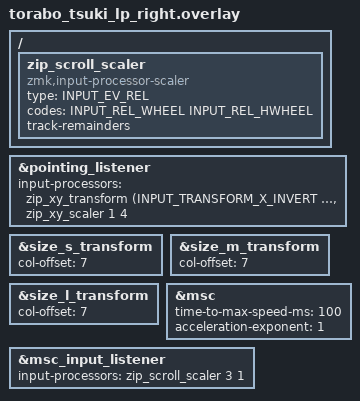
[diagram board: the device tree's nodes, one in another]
#include "torabo_tsuki_lp.dtsi"
#include <input/processors.dtsi>
#include <dt-bindings/zmk/input_transform.h>

&pointing_listener {
    input-processors = <
      &zip_xy_transform (INPUT_TRANSFORM_X_INVERT | INPUT_TRANSFORM_Y_INVERT)
      &zip_xy_scaler 1 4
    >;
};

&size_s_transform {
    col-offset = <7>;
};

&size_m_transform {
    col-offset = <7>;
};

&size_l_transform {
    col-offset = <7>;
};

#include <zephyr/dt-bindings/input/input-event-codes.h>

/ {
    zip_scroll_scaler: zip_scroll_scaler {
        compatible = "zmk,input-processor-scaler";
        #input-processor-cells = <2>;
        type = <INPUT_EV_REL>;
        codes = <INPUT_REL_WHEEL INPUT_REL_HWHEEL>;
        track-remainders;
    };
};

&msc {
    time-to-max-speed-ms = <100>;
    acceleration-exponent = <1>;
};

&msc_input_listener {
    input-processors = <&zip_scroll_scaler 3 1>;
};
